AUTOSAR XML (schema 4-2-2)
package /ComponentTypes
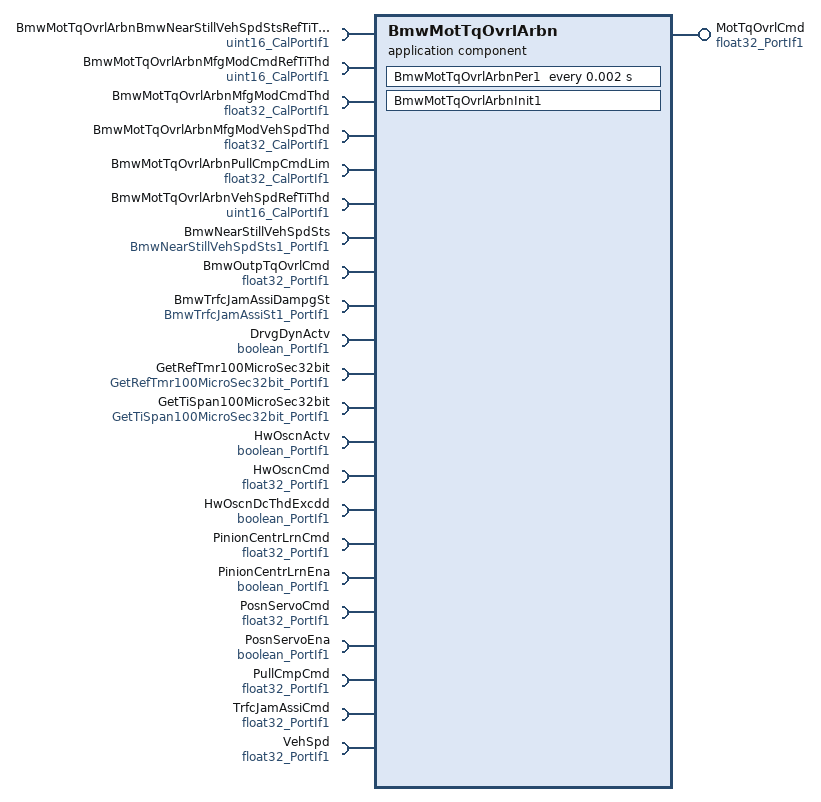
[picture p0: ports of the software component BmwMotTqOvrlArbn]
  application sw component type BmwMotTqOvrlArbn
    provide port MotTqOvrlCmd: nonqueued-sender-com-spec{data-element=Val, init-value=0}, provided-interface=float32_PortIf1
    22 x require port:
      BmwMotTqOvrlArbnBmwNearStillVehSpdStsRefTiThd: parameter-require-com-spec{init-value=10, parameter=Val}, required-interface=uint16_CalPortIf1
      BmwMotTqOvrlArbnMfgModCmdRefTiThd: parameter-require-com-spec{init-value=10, parameter=Val}, required-interface=uint16_CalPortIf1
      BmwMotTqOvrlArbnMfgModCmdThd: parameter-require-com-spec{init-value=0, parameter=Val}, required-interface=float32_CalPortIf1
      BmwMotTqOvrlArbnMfgModVehSpdThd: parameter-require-com-spec{init-value=10, parameter=Val}, required-interface=float32_CalPortIf1
      BmwMotTqOvrlArbnPullCmpCmdLim: parameter-require-com-spec{init-value=8.8, parameter=Val}, required-interface=float32_CalPortIf1
      BmwMotTqOvrlArbnVehSpdRefTiThd: parameter-require-com-spec{init-value=10, parameter=Val}, required-interface=uint16_CalPortIf1
      BmwNearStillVehSpdSts: nonqueued-receiver-com-spec{data-element=Val, filter=data-filter-type=ALWAYS, init-value=15}, required-interface=BmwNearStillVehSpdSts1_PortIf1
      BmwOutpTqOvrlCmd: nonqueued-receiver-com-spec{data-element=Val, filter=data-filter-type=ALWAYS, init-value=0}, required-interface=float32_PortIf1
      BmwTrfcJamAssiDampgSt: nonqueued-receiver-com-spec{data-element=Val, filter=data-filter-type=ALWAYS, init-value=1}, required-interface=BmwTrfcJamAssiSt1_PortIf1
      DrvgDynActv: nonqueued-receiver-com-spec{data-element=Logl, filter=data-filter-type=ALWAYS, init-value=0}, required-interface=boolean_PortIf1
      GetRefTmr100MicroSec32bit: client-com-spec=Oper, required-interface=GetRefTmr100MicroSec32bit_PortIf1
      GetTiSpan100MicroSec32bit: client-com-spec=Oper, required-interface=GetTiSpan100MicroSec32bit_PortIf1
      HwOscnActv: nonqueued-receiver-com-spec{data-element=Logl, filter=data-filter-type=ALWAYS, init-value=0}, required-interface=boolean_PortIf1
      HwOscnCmd: nonqueued-receiver-com-spec{data-element=Val, filter=data-filter-type=ALWAYS, init-value=0}, required-interface=float32_PortIf1
      HwOscnDcThdExcdd: nonqueued-receiver-com-spec{data-element=Logl, filter=data-filter-type=ALWAYS, init-value=0}, required-interface=boolean_PortIf1
      PinionCentrLrnCmd: nonqueued-receiver-com-spec{data-element=Val, filter=data-filter-type=ALWAYS, init-value=0}, required-interface=float32_PortIf1
      PinionCentrLrnEna: nonqueued-receiver-com-spec{data-element=Logl, filter=data-filter-type=ALWAYS, init-value=0}, required-interface=boolean_PortIf1
      PosnServoCmd: nonqueued-receiver-com-spec{data-element=Val, filter=data-filter-type=ALWAYS, init-value=0}, required-interface=float32_PortIf1
      PosnServoEna: nonqueued-receiver-com-spec{data-element=Logl, filter=data-filter-type=ALWAYS, init-value=0}, required-interface=boolean_PortIf1
      PullCmpCmd: nonqueued-receiver-com-spec{data-element=Val, filter=data-filter-type=ALWAYS, init-value=0}, required-interface=float32_PortIf1
      TrfcJamAssiCmd: nonqueued-receiver-com-spec{data-element=Val, filter=data-filter-type=ALWAYS, init-value=0}, required-interface=float32_PortIf1
      VehSpd: nonqueued-receiver-com-spec{data-element=Val, filter=data-filter-type=ALWAYS, init-value=0}, required-interface=float32_PortIf1
    behavior BmwMotTqOvrlArbn_InternalBehavior
      ar-typed-per-instance-memorys:
        4 x data, all with sw-calibration-access=READ-ONLY:
          BmwNearStillVehSpdStsCdnRefTi: type=uint32
          FctlErrStVari: type=boolean
          MfgModCmdCdnRefTi: type=uint32
          VehSpdCdnRefTi: type=uint32
      init event BmwMotTqOvrlArbn_InitEvent: start-on-event=BmwMotTqOvrlArbnInit1
      timing event TMT_BmwMotTqOvrlArbnPer1: start-on-event=BmwMotTqOvrlArbnPer1, period=0.002
      port-api-options:
        enable-take-address=false, error-handling=NO-TRANSFORMER-ERROR-HANDLING, indirect-api=false, port=BmwMotTqOvrlArbnBmwNearStillVehSpdStsRefTiThd
        enable-take-address=false, error-handling=NO-TRANSFORMER-ERROR-HANDLING, indirect-api=false, port=BmwMotTqOvrlArbnMfgModCmdRefTiThd
        enable-take-address=false, error-handling=NO-TRANSFORMER-ERROR-HANDLING, indirect-api=false, port=BmwMotTqOvrlArbnMfgModCmdThd
        enable-take-address=false, error-handling=NO-TRANSFORMER-ERROR-HANDLING, indirect-api=false, port=BmwMotTqOvrlArbnMfgModVehSpdThd
        enable-take-address=false, error-handling=NO-TRANSFORMER-ERROR-HANDLING, indirect-api=false, port=BmwMotTqOvrlArbnPullCmpCmdLim
        enable-take-address=false, error-handling=NO-TRANSFORMER-ERROR-HANDLING, indirect-api=false, port=BmwMotTqOvrlArbnVehSpdRefTiThd
        enable-take-address=false, error-handling=NO-TRANSFORMER-ERROR-HANDLING, indirect-api=false, port=BmwNearStillVehSpdSts
        enable-take-address=false, error-handling=NO-TRANSFORMER-ERROR-HANDLING, indirect-api=false, port=BmwOutpTqOvrlCmd
        enable-take-address=false, error-handling=NO-TRANSFORMER-ERROR-HANDLING, indirect-api=false, port=BmwTrfcJamAssiDampgSt
        enable-take-address=false, error-handling=NO-TRANSFORMER-ERROR-HANDLING, indirect-api=false, port=DrvgDynActv
        enable-take-address=false, error-handling=NO-TRANSFORMER-ERROR-HANDLING, indirect-api=false, port=GetRefTmr100MicroSec32bit
        enable-take-address=false, error-handling=NO-TRANSFORMER-ERROR-HANDLING, indirect-api=false, port=GetTiSpan100MicroSec32bit
        enable-take-address=false, error-handling=NO-TRANSFORMER-ERROR-HANDLING, indirect-api=false, port=HwOscnActv
        enable-take-address=false, error-handling=NO-TRANSFORMER-ERROR-HANDLING, indirect-api=false, port=HwOscnCmd
        enable-take-address=false, error-handling=NO-TRANSFORMER-ERROR-HANDLING, indirect-api=false, port=HwOscnDcThdExcdd
        enable-take-address=false, error-handling=NO-TRANSFORMER-ERROR-HANDLING, indirect-api=false, port=MotTqOvrlCmd
        enable-take-address=false, error-handling=NO-TRANSFORMER-ERROR-HANDLING, indirect-api=false, port=PinionCentrLrnCmd
        enable-take-address=false, error-handling=NO-TRANSFORMER-ERROR-HANDLING, indirect-api=false, port=PinionCentrLrnEna
        enable-take-address=false, error-handling=NO-TRANSFORMER-ERROR-HANDLING, indirect-api=false, port=PosnServoCmd
        enable-take-address=false, error-handling=NO-TRANSFORMER-ERROR-HANDLING, indirect-api=false, port=PosnServoEna
        enable-take-address=false, error-handling=NO-TRANSFORMER-ERROR-HANDLING, indirect-api=false, port=PullCmpCmd
        enable-take-address=false, error-handling=NO-TRANSFORMER-ERROR-HANDLING, indirect-api=false, port=TrfcJamAssiCmd
        enable-take-address=false, error-handling=NO-TRANSFORMER-ERROR-HANDLING, indirect-api=false, port=VehSpd
      runnable BmwMotTqOvrlArbnInit1
      runnable BmwMotTqOvrlArbnPer1
        data-receive-point-by-arguments:
          14 x access:
            REC_BmwNearStillVehSpdSts_Val: accessed-variable=BmwNearStillVehSpdSts.Val
            REC_BmwOutpTqOvrlCmd_Val: accessed-variable=BmwOutpTqOvrlCmd.Val
            REC_BmwTrfcJamAssiDampgSt_Val: accessed-variable=BmwTrfcJamAssiDampgSt.Val
            REC_DrvgDynActv_Logl: accessed-variable=DrvgDynActv.Logl
            REC_HwOscnActv_Logl: accessed-variable=HwOscnActv.Logl
            REC_HwOscnCmd_Val: accessed-variable=HwOscnCmd.Val
            REC_HwOscnDcThdExcdd_Logl: accessed-variable=HwOscnDcThdExcdd.Logl
            REC_PinionCentrLrnCmd_Val: accessed-variable=PinionCentrLrnCmd.Val
            REC_PinionCentrLrnEna_Logl: accessed-variable=PinionCentrLrnEna.Logl
            REC_PosnServoCmd_Val: accessed-variable=PosnServoCmd.Val
            REC_PosnServoEna_Logl: accessed-variable=PosnServoEna.Logl
            REC_PullCmpCmd_Val: accessed-variable=PullCmpCmd.Val
            REC_TrfcJamAssiCmd_Val: accessed-variable=TrfcJamAssiCmd.Val
            REC_VehSpd_Val: accessed-variable=VehSpd.Val
        data-send-points:
          access SEND_MotTqOvrlCmd_Val: accessed-variable=MotTqOvrlCmd.Val
        sync call SC_GetRefTmr100MicroSec32bit_Oper: operation=GetRefTmr100MicroSec32bit.Oper, timeout=0
        sync call SC_GetTiSpan100MicroSec32bit_Oper: operation=GetTiSpan100MicroSec32bit.Oper, timeout=0
  swc implementation BmwMotTqOvrlArbn_Implementation: behavior=BmwMotTqOvrlArbn_InternalBehavior
    code-descriptors:
      code Default: artifact-descriptors=autosar-engineering-object={short-label=Default, category=SWSRC}
